# STM32L412C8T6 register map
File version: 1.0
Registers are 32-bit, access not given, reset 0x0 unless marked. A register's access mark holds for its fields unless they carry their own. Offsets are from the block's base; [hi:lo] are bit positions; {n}, {i} and the like mark numbered series; 'fields as' and 'values as' point back to an identical list.

## SAI1
Base 0x40015400
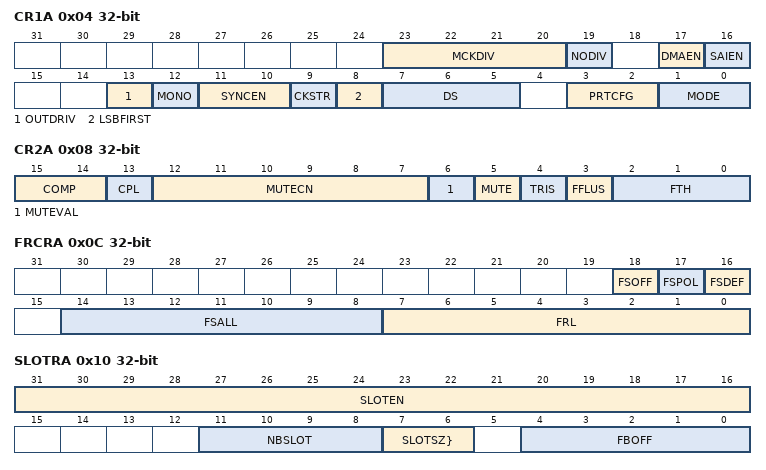
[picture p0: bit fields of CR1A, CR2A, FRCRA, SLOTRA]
0x04 CR1A
  [23:20] MCKDIV, [19] NODIV, [17] DMAEN, [16] SAIEN, [13] OUTDRIV, [12] MONO, [11:10] SYNCEN, [9] CKSTR, [8] LSBFIRST, [7:5] DS, [3:2] PRTCFG, [1:0] MODE
0x08 CR2A
  [15:14] COMP, [13] CPL, [12:7] MUTECN, [6] MUTEVAL, [5] MUTE, [4] TRIS, [3] FFLUS, [2:0] FTH
0x0C FRCRA
  [18] FSOFF, [17] FSPOL, [16] FSDEF, [14:8] FSALL, [7:0] FRL
0x10 SLOTRA
  [31:16] SLOTEN, [11:8] NBSLOT, [7:6] SLOTSZ}, [4:0] FBOFF
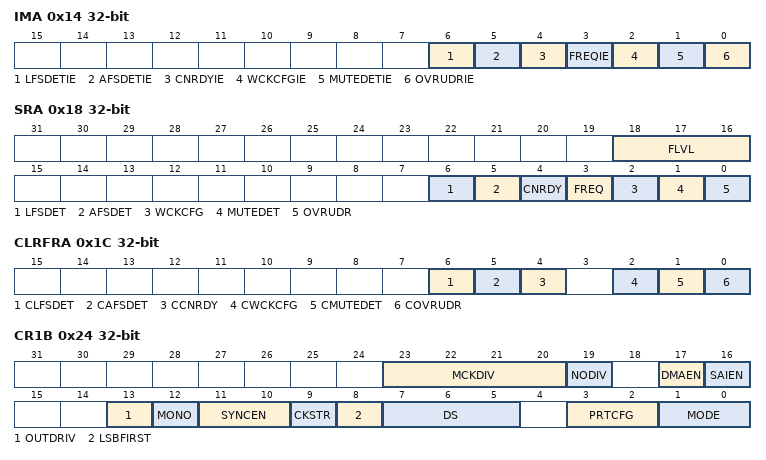
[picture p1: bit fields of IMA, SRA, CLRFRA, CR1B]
0x14 IMA
  [6] LFSDETIE, [5] AFSDETIE, [4] CNRDYIE, [3] FREQIE, [2] WCKCFGIE, [1] MUTEDETIE, [0] OVRUDRIE
0x18 SRA
  [18:16] FLVL, [6] LFSDET, [5] AFSDET, [4] CNRDY, [3] FREQ, [2] WCKCFG, [1] MUTEDET, [0] OVRUDR
0x1C CLRFRA
  [6] CLFSDET, [5] CAFSDET, [4] CCNRDY, [2] CWCKCFG, [1] CMUTEDET, [0] COVRUDR
0x20 DRA
  [31:0] DATA
0x24 CR1B
  fields as CR1A
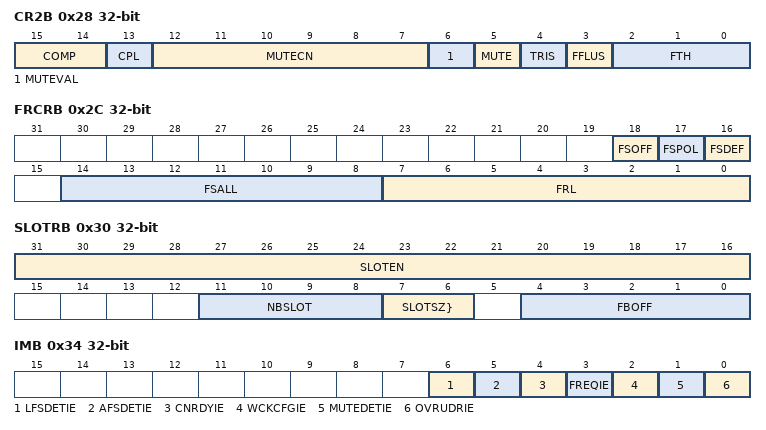
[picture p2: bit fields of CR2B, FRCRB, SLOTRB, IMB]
0x28 CR2B
  fields as CR2A
0x2C FRCRB
  [18] FSOFF, [17] FSPOL, [16] FSDEF, [14:8] FSALL, [7:0] FRL
0x30 SLOTRB
  [31:16] SLOTEN, [11:8] NBSLOT, [7:6] SLOTSZ}, [4:0] FBOFF
0x34 IMB
  fields as IMA
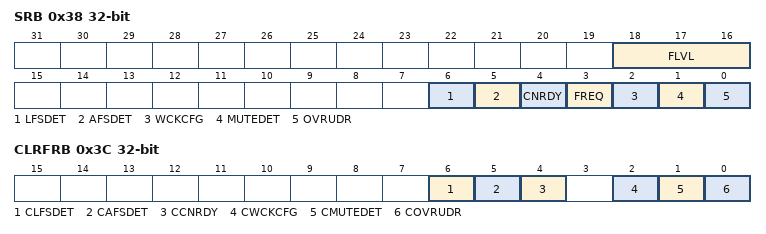
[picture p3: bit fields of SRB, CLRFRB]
0x38 SRB
  fields as SRA
0x3C CLRFRB
  fields as CLRFRA
0x40 DRB
  [31:0] DATA

## DFSDM1
Base 0x40016000
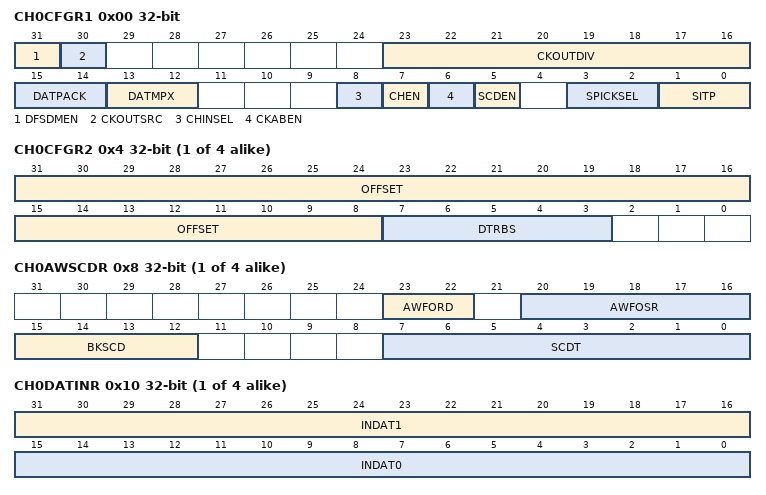
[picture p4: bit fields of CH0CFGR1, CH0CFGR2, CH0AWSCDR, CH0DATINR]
0x00 CH0CFGR1
  [31] DFSDMEN, [30] CKOUTSRC, [23:16] CKOUTDIV, [15:14] DATPACK, [13:12] DATMPX, [8] CHINSEL, [7] CHEN, [6] CKABEN, [5] SCDEN, [3:2] SPICKSEL, [1:0] SITP
{0x4+0x20*i} CH{i}CFGR2 (i=0..3)
  [31:8] OFFSET, [7:3] DTRBS
{0x8+0x20*i} CH{i}AWSCDR (i=0..3)
  [23:22] AWFORD, [20:16] AWFOSR, [15:12] BKSCD, [7:0] SCDT
{0xC+0x20*i} CH{i}WDATR (i=0..3)
  [15:0] WDATA
{0x10+0x20*i} CH{i}DATINR (i=0..3)
  [31:16] INDAT1, [15:0] INDAT0
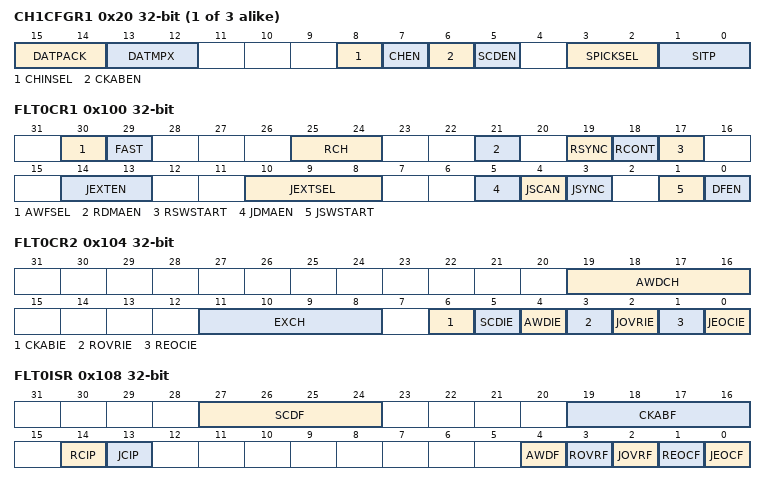
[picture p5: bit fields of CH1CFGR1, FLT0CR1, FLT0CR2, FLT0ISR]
{0x0+0x20*i} CH{i}CFGR1 (i=1..3)
  [15:14] DATPACK, [13:12] DATMPX, [8] CHINSEL, [7] CHEN, [6] CKABEN, [5] SCDEN, [3:2] SPICKSEL, [1:0] SITP
0x100 FLT0CR1
  [30] AWFSEL, [29] FAST, [25:24] RCH, [21] RDMAEN, [19] RSYNC, [18] RCONT, [17] RSWSTART, [14:13] JEXTEN, [10:8] JEXTSEL, [5] JDMAEN, [4] JSCAN, [3] JSYNC, [1] JSWSTART, [0] DFEN
0x104 FLT0CR2
  [19:16] AWDCH, [11:8] EXCH, [6] CKABIE, [5] SCDIE, [4] AWDIE, [3] ROVRIE, [2] JOVRIE, [1] REOCIE, [0] JEOCIE
0x108 FLT0ISR
  [27:24] SCDF, [19:16] CKABF, [14] RCIP, [13] JCIP, [4] AWDF, [3] ROVRF, [2] JOVRF, [1] REOCF, [0] JEOCF
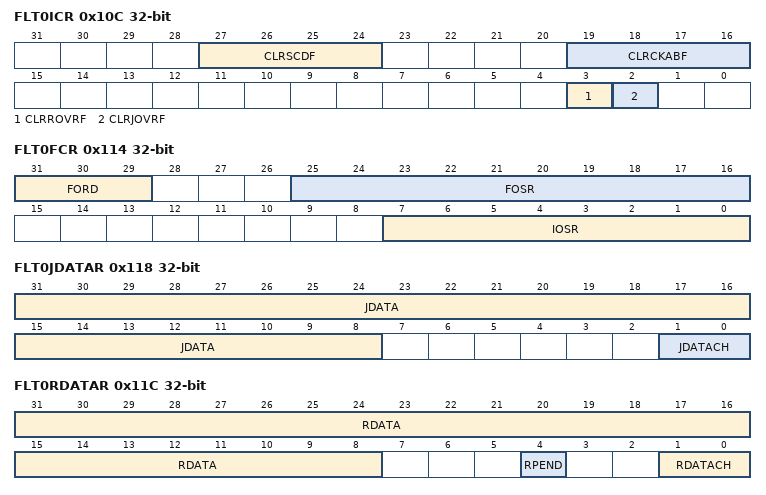
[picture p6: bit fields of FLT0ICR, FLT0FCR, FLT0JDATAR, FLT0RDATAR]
0x10C FLT0ICR
  [27:24] CLRSCDF, [19:16] CLRCKABF, [3] CLRROVRF, [2] CLRJOVRF
0x110 FLT0JCHGR
  [3:0] JCHG
0x114 FLT0FCR
  [31:29] FORD, [25:16] FOSR, [7:0] IOSR
0x118 FLT0JDATAR
  [31:8] JDATA, [1:0] JDATACH
0x11C FLT0RDATAR
  [31:8] RDATA, [4] RPEND, [1:0] RDATACH
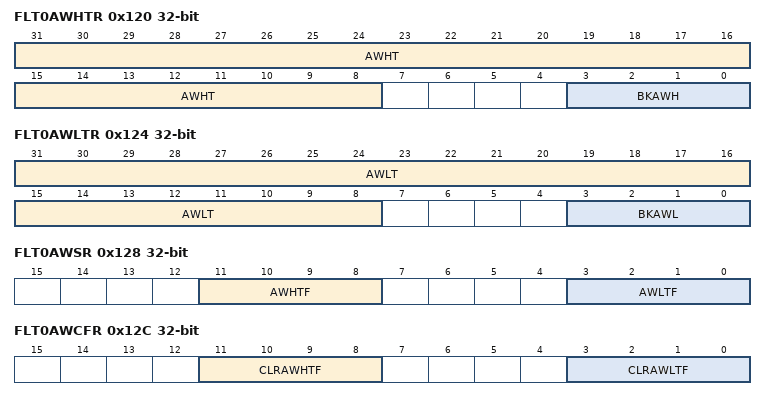
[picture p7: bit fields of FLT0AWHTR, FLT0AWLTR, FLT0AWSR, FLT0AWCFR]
0x120 FLT0AWHTR
  [31:8] AWHT, [3:0] BKAWH
0x124 FLT0AWLTR
  [31:8] AWLT, [3:0] BKAWL
0x128 FLT0AWSR
  [11:8] AWHTF, [3:0] AWLTF
0x12C FLT0AWCFR
  [11:8] CLRAWHTF, [3:0] CLRAWLTF
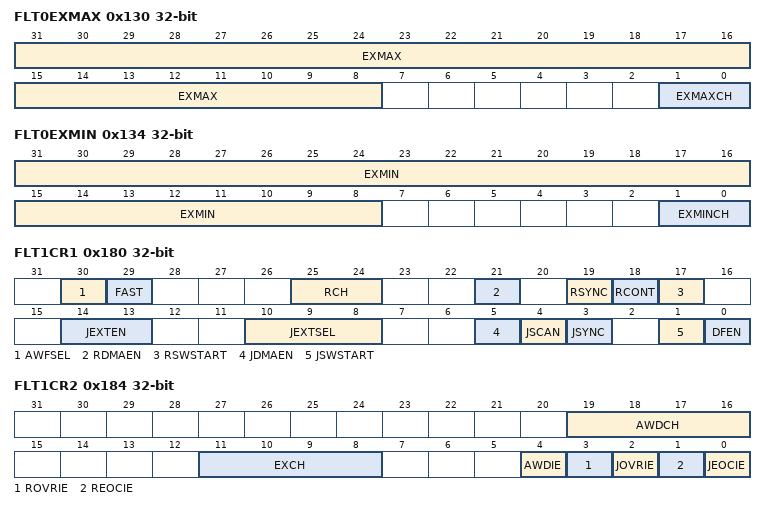
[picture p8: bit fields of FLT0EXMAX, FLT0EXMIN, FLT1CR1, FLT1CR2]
0x130 FLT0EXMAX
  [31:8] EXMAX, [1:0] EXMAXCH
0x134 FLT0EXMIN
  [31:8] EXMIN, [1:0] EXMINCH
0x138 FLT0CNVTIMR
  [31:4] CNVCNT
0x180 FLT1CR1
  fields as FLT0CR1
0x184 FLT1CR2
  [19:16] AWDCH, [11:8] EXCH, [4] AWDIE, [3] ROVRIE, [2] JOVRIE, [1] REOCIE, [0] JEOCIE
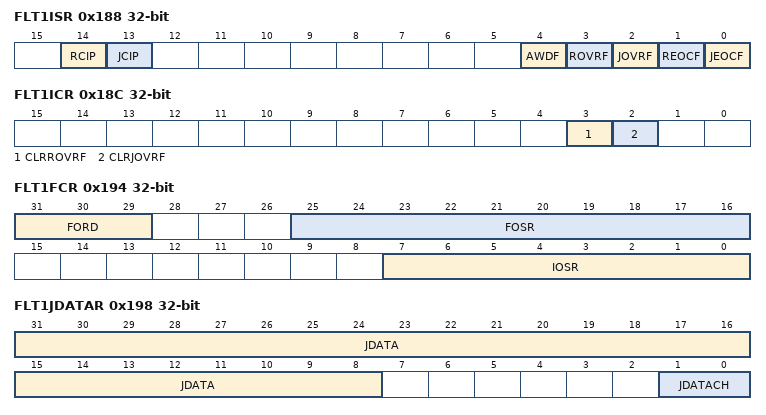
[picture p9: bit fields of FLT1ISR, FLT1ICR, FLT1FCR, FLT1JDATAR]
0x188 FLT1ISR
  [14] RCIP, [13] JCIP, [4] AWDF, [3] ROVRF, [2] JOVRF, [1] REOCF, [0] JEOCF
0x18C FLT1ICR
  [3] CLRROVRF, [2] CLRJOVRF
0x190 FLT1JCHGR
  [3:0] JCHG
0x194 FLT1FCR
  [31:29] FORD, [25:16] FOSR, [7:0] IOSR
0x198 FLT1JDATAR
  [31:8] JDATA, [1:0] JDATACH
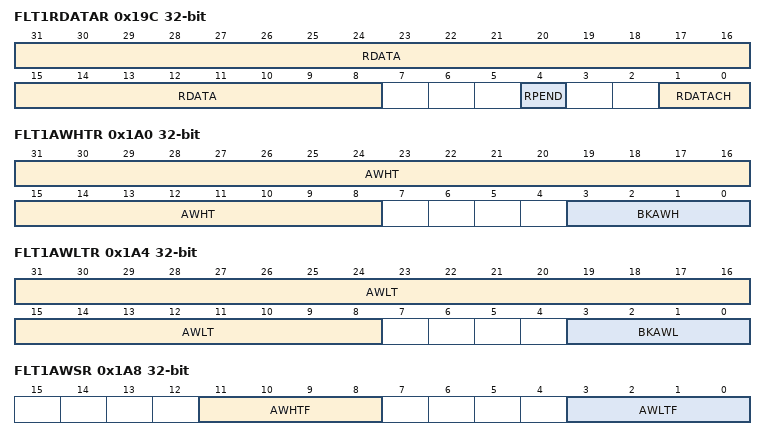
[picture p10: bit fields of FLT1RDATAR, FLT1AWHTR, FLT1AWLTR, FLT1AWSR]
0x19C FLT1RDATAR
  [31:8] RDATA, [4] RPEND, [1:0] RDATACH
0x1A0 FLT1AWHTR
  [31:8] AWHT, [3:0] BKAWH
0x1A4 FLT1AWLTR
  [31:8] AWLT, [3:0] BKAWL
0x1A8 FLT1AWSR
  [11:8] AWHTF, [3:0] AWLTF
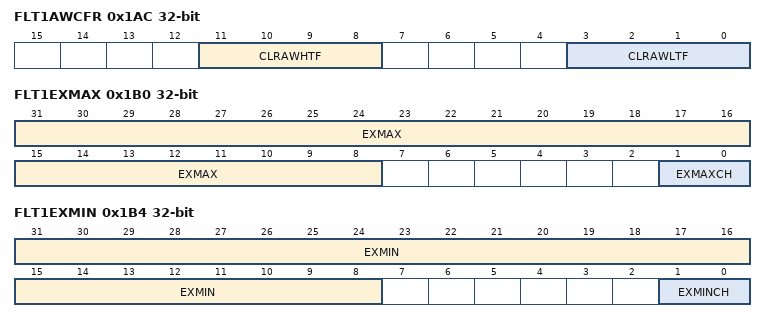
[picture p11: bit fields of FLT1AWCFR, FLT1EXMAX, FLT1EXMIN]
0x1AC FLT1AWCFR
  [11:8] CLRAWHTF, [3:0] CLRAWLTF
0x1B0 FLT1EXMAX
  [31:8] EXMAX, [1:0] EXMAXCH
0x1B4 FLT1EXMIN
  [31:8] EXMIN, [1:0] EXMINCH
0x1B8 FLT1CNVTIMR
  [31:4] CNVCNT

## DMA1
Base 0x40020000
Same registers: DMA2 0x40020400
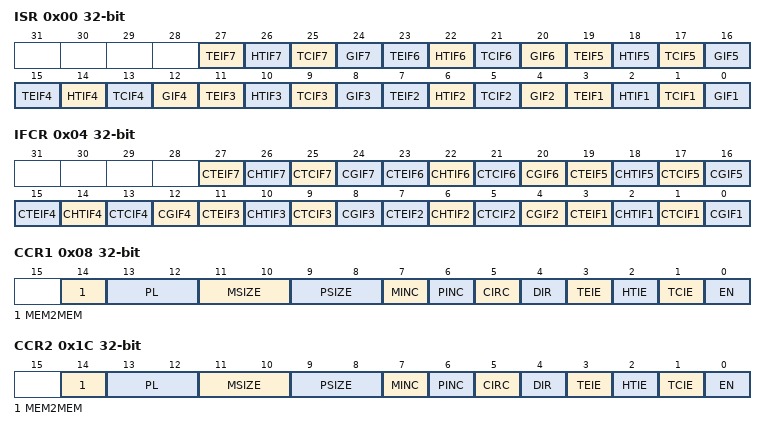
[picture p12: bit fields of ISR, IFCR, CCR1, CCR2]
0x00 ISR
  [4n-1] TEIF{n} (n=1..7), [4n-2] HTIF{n} (n=1..7), [4n-3] TCIF{n} (n=1..7), [4n-4] GIF{n} (n=1..7)
0x04 IFCR
  [4n-1] CTEIF{n} (n=1..7), [4n-2] CHTIF{n} (n=1..7), [4n-3] CTCIF{n} (n=1..7), [4n-4] CGIF{n} (n=1..7)
0x08 CCR1
  [14] MEM2MEM, [13:12] PL, [11:10] MSIZE, [9:8] PSIZE, [7] MINC, [6] PINC, [5] CIRC, [4] DIR, [3] TEIE, [2] HTIE, [1] TCIE, [0] EN
0x0C CNDTR1
  [15:0] NDTR
0x10 CPAR1
  [31:0] PA
{0x0+0x14*i} CMAR{i} (i=1..7)
  [31:0] MA
0x1C CCR2
  fields as CCR1
0x20 CNDTR2
  [15:0] NDTR
0x24 CPAR2
  [31:0] PA
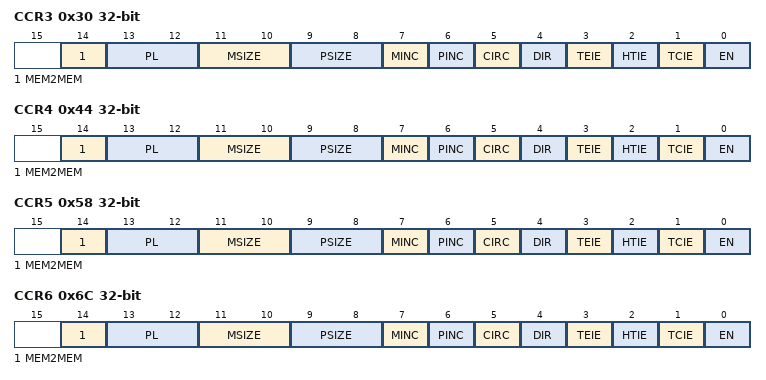
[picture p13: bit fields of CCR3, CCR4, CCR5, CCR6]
0x30 CCR3
  fields as CCR1
0x34 CNDTR3
  [15:0] NDTR
0x38 CPAR3
  [31:0] PA
0x44 CCR4
  fields as CCR1
0x48 CNDTR4
  [15:0] NDTR
0x4C CPAR4
  [31:0] PA
0x58 CCR5
  fields as CCR1
0x5C CNDTR5
  [15:0] NDTR
0x60 CPAR5
  [31:0] PA
0x6C CCR6
  fields as CCR1
0x70 CNDTR6
  [15:0] NDTR
0x74 CPAR6
  [31:0] PA
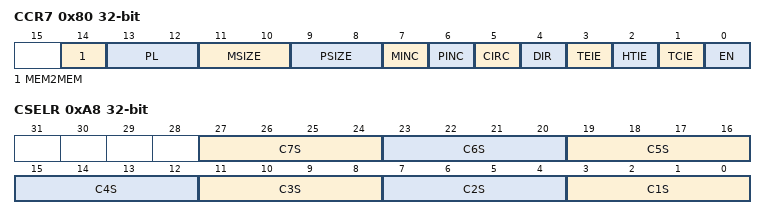
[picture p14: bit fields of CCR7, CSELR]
0x80 CCR7
  fields as CCR1
0x84 CNDTR7
  [15:0] NDTR
0x88 CPAR7
  [31:0] PA
0xA8 CSELR
  [4n-1:4n-4] C{n}S (n=1..7)
